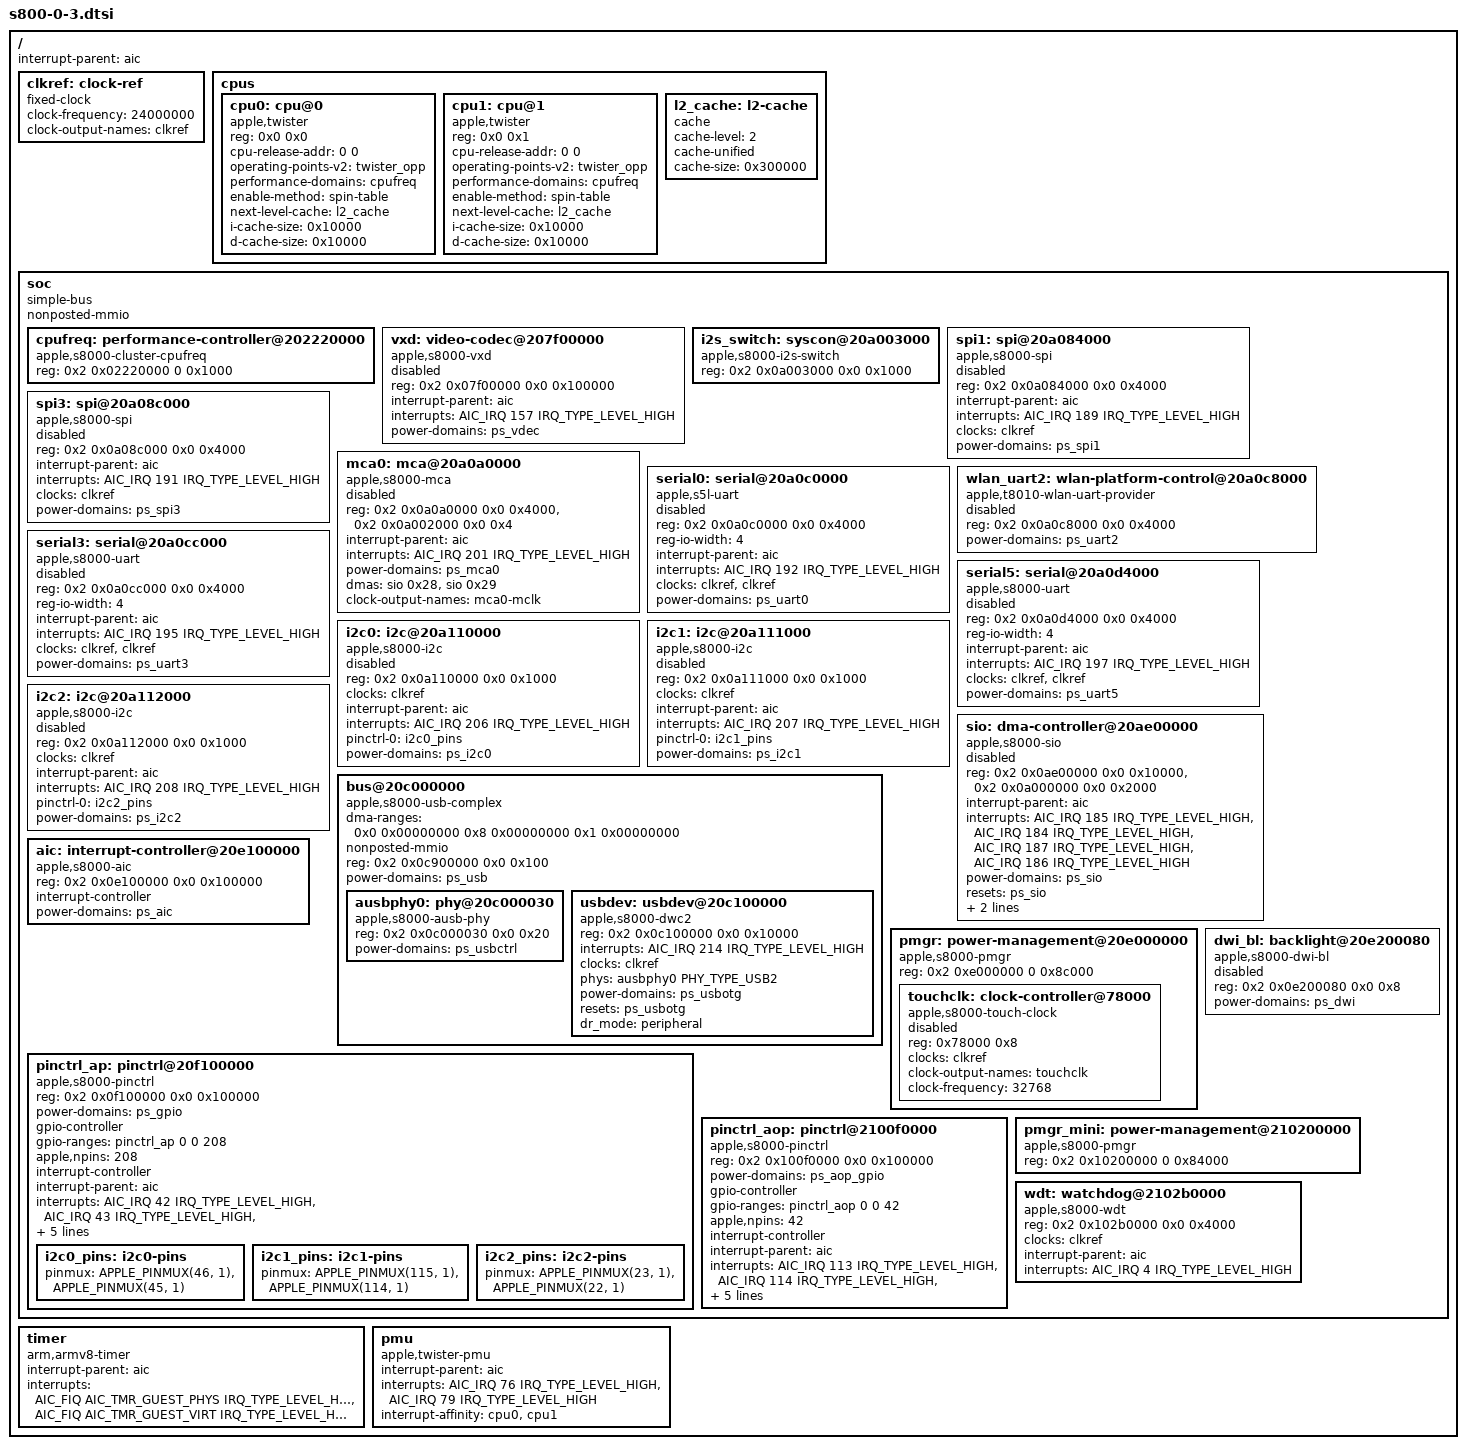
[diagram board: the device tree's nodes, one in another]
// SPDX-License-Identifier: GPL-2.0+ OR MIT
/*
 * Apple S8000/S8003 "A9" SoC
 *
 * This file contains parts common to both variants of A9
 *
 * Copyright (c) 2022, Konrad Dybcio <konradybcio@kernel.org>
 */

#include <dt-bindings/gpio/gpio.h>
#include <dt-bindings/interrupt-controller/apple-aic.h>
#include <dt-bindings/interrupt-controller/irq.h>
#include <dt-bindings/phy/phy.h>
#include <dt-bindings/pinctrl/apple.h>

/ {
	interrupt-parent = <&aic>;
	#address-cells = <2>;
	#size-cells = <2>;

	clkref: clock-ref {
		compatible = "fixed-clock";
		#clock-cells = <0>;
		clock-frequency = <24000000>;
		clock-output-names = "clkref";
	};

	cpus {
		#address-cells = <2>;
		#size-cells = <0>;

		cpu0: cpu@0 {
			compatible = "apple,twister";
			reg = <0x0 0x0>;
			cpu-release-addr = <0 0>; /* To be filled in by loader */
			operating-points-v2 = <&twister_opp>;
			performance-domains = <&cpufreq>;
			enable-method = "spin-table";
			device_type = "cpu";
			next-level-cache = <&l2_cache>;
			i-cache-size = <0x10000>;
			d-cache-size = <0x10000>;
		};

		cpu1: cpu@1 {
			compatible = "apple,twister";
			reg = <0x0 0x1>;
			cpu-release-addr = <0 0>; /* To be filled in by loader */
			operating-points-v2 = <&twister_opp>;
			performance-domains = <&cpufreq>;
			enable-method = "spin-table";
			device_type = "cpu";
			next-level-cache = <&l2_cache>;
			i-cache-size = <0x10000>;
			d-cache-size = <0x10000>;
		};

		l2_cache: l2-cache {
			compatible = "cache";
			cache-level = <2>;
			cache-unified;
			cache-size = <0x300000>;
		};
	};

	soc {
		compatible = "simple-bus";
		#address-cells = <2>;
		#size-cells = <2>;
		nonposted-mmio;
		ranges;

		cpufreq: performance-controller@202220000 {
			compatible = "apple,s8000-cluster-cpufreq", "apple,t8103-cluster-cpufreq", "apple,cluster-cpufreq";
			reg = <0x2 0x02220000 0 0x1000>;
			#performance-domain-cells = <0>;
		};

		/*
		 * Imagination MSVDX ("VXD") H.264 decoder, ADT vxd@7F00000. It
		 * has its own two-level GART, so no DART.
		 */
		vxd: video-codec@207f00000 {
			compatible = "apple,s8000-vxd";
			reg = <0x2 0x07f00000 0x0 0x100000>;
			interrupt-parent = <&aic>;
			interrupts = <AIC_IRQ 157 IRQ_TYPE_LEVEL_HIGH>;
			power-domains = <&ps_vdec>;
			status = "disabled";
		};

		i2s_switch: syscon@20a003000 {
			compatible = "apple,s8000-i2s-switch", "syscon";
			reg = <0x2 0x0a003000 0x0 0x1000>;
		};

		spi1: spi@20a084000 {
			compatible = "apple,s8000-spi", "apple,spi";
			reg = <0x2 0x0a084000 0x0 0x4000>;
			interrupt-parent = <&aic>;
			interrupts = <AIC_IRQ 189 IRQ_TYPE_LEVEL_HIGH>;
			clocks = <&clkref>;
			power-domains = <&ps_spi1>;
			#address-cells = <1>;
			#size-cells = <0>;
			status = "disabled";
		};

		spi3: spi@20a08c000 {
			compatible = "apple,s8000-spi", "apple,spi";
			reg = <0x2 0x0a08c000 0x0 0x4000>;
			interrupt-parent = <&aic>;
			interrupts = <AIC_IRQ 191 IRQ_TYPE_LEVEL_HIGH>;
			clocks = <&clkref>;
			power-domains = <&ps_spi3>;
			#address-cells = <1>;
			#size-cells = <0>;
			status = "disabled";
		};

		/* SmartIO DMA endpoints 0x28 (TX) and 0x29 (RX), from the ADT. */
		mca0: mca@20a0a0000 {
			compatible = "apple,s8000-mca";
			reg = <0x2 0x0a0a0000 0x0 0x4000>,
			      <0x2 0x0a002000 0x0 0x4>;
			reg-names = "mca", "mclk";
			interrupt-parent = <&aic>;
			interrupts = <AIC_IRQ 201 IRQ_TYPE_LEVEL_HIGH>;
			power-domains = <&ps_mca0>;
			dmas = <&sio 0x28>, <&sio 0x29>;
			dma-names = "tx", "rx";
			#clock-cells = <0>;
			clock-output-names = "mca0-mclk";
			#sound-dai-cells = <0>;
			status = "disabled";
		};

		serial0: serial@20a0c0000 {
			compatible = "apple,s5l-uart";
			reg = <0x2 0x0a0c0000 0x0 0x4000>;
			reg-io-width = <4>;
			interrupt-parent = <&aic>;
			interrupts = <AIC_IRQ 192 IRQ_TYPE_LEVEL_HIGH>;
			/* Use the bootloader-enabled clocks for now. */
			clocks = <&clkref>, <&clkref>;
			clock-names = "uart", "clk_uart_baud0";
			power-domains = <&ps_uart0>;
			status = "disabled";
		};

		/*
		 * uart2 carries the ADT's "wlan" node (wlan-pcie-uart,bcm4355):
		 * the platform-control function of the PCIe Wi-Fi module.
		 */
		wlan_uart2: wlan-platform-control@20a0c8000 {
			compatible = "apple,t8010-wlan-uart-provider";
			reg = <0x2 0x0a0c8000 0x0 0x4000>;
			power-domains = <&ps_uart2>;
			status = "disabled";
		};

		serial3: serial@20a0cc000 {
			compatible = "apple,s8000-uart", "apple,t8010-uart", "apple,s5l-uart";
			reg = <0x2 0x0a0cc000 0x0 0x4000>;
			reg-io-width = <4>;
			interrupt-parent = <&aic>;
			interrupts = <AIC_IRQ 195 IRQ_TYPE_LEVEL_HIGH>;
			/* Use the bootloader-enabled clocks for now. */
			clocks = <&clkref>, <&clkref>;
			clock-names = "uart", "clk_uart_baud0";
			power-domains = <&ps_uart3>;
			status = "disabled";
		};

		serial5: serial@20a0d4000 {
			compatible = "apple,s8000-uart", "apple,t8010-uart", "apple,s5l-uart";
			reg = <0x2 0x0a0d4000 0x0 0x4000>;
			reg-io-width = <4>;
			interrupt-parent = <&aic>;
			interrupts = <AIC_IRQ 197 IRQ_TYPE_LEVEL_HIGH>;
			/* Use the bootloader-enabled clocks for now. */
			clocks = <&clkref>, <&clkref>;
			clock-names = "uart", "clk_uart_baud0";
			power-domains = <&ps_uart5>;
			status = "disabled";
		};

		i2c0: i2c@20a110000 {
			compatible = "apple,s8000-i2c", "apple,i2c";
			reg = <0x2 0x0a110000 0x0 0x1000>;
			clocks = <&clkref>;
			interrupt-parent = <&aic>;
			interrupts = <AIC_IRQ 206 IRQ_TYPE_LEVEL_HIGH>;
			pinctrl-0 = <&i2c0_pins>;
			pinctrl-names = "default";
			power-domains = <&ps_i2c0>;
			#address-cells = <1>;
			#size-cells = <0>;
			status = "disabled";
		};

		i2c1: i2c@20a111000 {
			compatible = "apple,s8000-i2c", "apple,i2c";
			reg = <0x2 0x0a111000 0x0 0x1000>;
			clocks = <&clkref>;
			interrupt-parent = <&aic>;
			interrupts = <AIC_IRQ 207 IRQ_TYPE_LEVEL_HIGH>;
			pinctrl-0 = <&i2c1_pins>;
			pinctrl-names = "default";
			power-domains = <&ps_i2c1>;
			#address-cells = <1>;
			#size-cells = <0>;
			status = "disabled";
		};

		i2c2: i2c@20a112000 {
			compatible = "apple,s8000-i2c", "apple,i2c";
			reg = <0x2 0x0a112000 0x0 0x1000>;
			clocks = <&clkref>;
			interrupt-parent = <&aic>;
			interrupts = <AIC_IRQ 208 IRQ_TYPE_LEVEL_HIGH>;
			pinctrl-0 = <&i2c2_pins>;
			pinctrl-names = "default";
			power-domains = <&ps_i2c2>;
			#address-cells = <1>;
			#size-cells = <0>;
			status = "disabled";
		};

		/* ADT /arm-io/sio: iop,s8000, AppleA7IOP version 1 */
		sio: dma-controller@20ae00000 {
			compatible = "apple,s8000-sio";
			reg = <0x2 0x0ae00000 0x0 0x10000>,
			      <0x2 0x0a000000 0x0 0x2000>;
			reg-names = "a7iop", "shim";
			interrupt-parent = <&aic>;
			interrupts = <AIC_IRQ 185 IRQ_TYPE_LEVEL_HIGH>,
				     <AIC_IRQ 184 IRQ_TYPE_LEVEL_HIGH>,
				     <AIC_IRQ 187 IRQ_TYPE_LEVEL_HIGH>,
				     <AIC_IRQ 186 IRQ_TYPE_LEVEL_HIGH>;
			power-domains = <&ps_sio>;
			resets = <&ps_sio>;
			firmware-name = "apple/s8000-smartio.bin";
			dma-channels = <64>;
			#dma-cells = <1>;
			status = "disabled";
		};

		bus@20c000000 {
			compatible = "apple,s8000-usb-complex", "apple,s5l8960x-usb-complex", "simple-pm-bus";
			#address-cells = <2>;
			#size-cells = <2>;
			dma-ranges = <0x0 0x00000000 0x8 0x00000000 0x1 0x00000000>;
			nonposted-mmio;
			ranges;

			reg = <0x2 0x0c900000 0x0 0x100>;
			power-domains = <&ps_usb>;

			ausbphy0: phy@20c000030 {
				compatible = "apple,s8000-ausb-phy", "apple,ausb-phy";
				reg = <0x2 0x0c000030 0x0 0x20>;
				power-domains = <&ps_usbctrl>;
				#phy-cells = <1>;
				/* Tunables to be filled by loader */
			};

			usbdev: usbdev@20c100000 {
				compatible = "apple,s8000-dwc2", "apple,dwc2";
				reg = <0x2 0x0c100000 0x0 0x10000>;
				interrupts = <AIC_IRQ 214 IRQ_TYPE_LEVEL_HIGH>;
				clocks = <&clkref>;
				clock-names = "otg";
				phys = <&ausbphy0 PHY_TYPE_USB2>;
				phy-names = "usb2-phy";
				power-domains = <&ps_usbotg>;
				resets = <&ps_usbotg>;
				dr_mode = "peripheral";
			};
#if 0
			ehci0: usb-ehci@20c200000 {
				compatible = "apple,s8000-ehci", "generic-ehci";
				reg = <0x2 0x0c200000 0x0 0x10000>;
				interrupts = <AIC_IRQ 215 IRQ_TYPE_LEVEL_HIGH>;
				power-domains = <&ps_usb2host0>;
			};

			ohci0: usb-ohci@20c300000 {
				compatible = "apple,s8000-ohci", "generic-ohci";
				reg = <0x2 0x0c300000 0x0 0x10000>;
				interrupts = <AIC_IRQ 216 IRQ_TYPE_LEVEL_HIGH>;
				power-domains = <&ps_usb2host0_ohci>;
			};

			ehci1: usb-ehci@20c400000 {
				compatible = "apple,s8000-ehci", "generic-ehci";
				reg = <0x2 0x0c400000 0x0 0x10000>;
				interrupts = <AIC_IRQ 217 IRQ_TYPE_LEVEL_HIGH>;
				power-domains = <&ps_usb2host1>;
			};

			ehci2: usb-ehci@20c500000 {
				compatible = "apple,s8000-ehci", "generic-ehci";
				reg = <0x2 0x0c500000 0x0 0x10000>;
				interrupts = <AIC_IRQ 218 IRQ_TYPE_LEVEL_HIGH>;
				power-domains = <&ps_usb2host2>;
			};
#endif
		};

		pmgr: power-management@20e000000 {
			compatible = "apple,s8000-pmgr", "apple,pmgr", "syscon", "simple-mfd";
			#address-cells = <1>;
			#size-cells = <1>;

			reg = <0x2 0xe000000 0 0x8c000>;

			touchclk: clock-controller@78000 {
				compatible = "apple,s8000-touch-clock", "apple,t8010-touch-clock";
				reg = <0x78000 0x8>;
				#clock-cells = <0>;
				clocks = <&clkref>;
				clock-output-names = "touchclk";
				clock-frequency = <32768>;
				status = "disabled";
			};
		};

		aic:interrupt-controller@20e100000 {
			compatible = "apple,s8000-aic", "apple,aic";
			reg = <0x2 0x0e100000 0x0 0x100000>;
			#interrupt-cells = <3>;
			interrupt-controller;
			power-domains = <&ps_aic>;
		};

		dwi_bl: backlight@20e200080 {
			compatible = "apple,s8000-dwi-bl", "apple,dwi-bl";
			reg = <0x2 0x0e200080 0x0 0x8>;
			power-domains = <&ps_dwi>;
			status = "disabled";
		};

		pinctrl_ap: pinctrl@20f100000 {
			compatible = "apple,s8000-pinctrl", "apple,pinctrl";
			reg = <0x2 0x0f100000 0x0 0x100000>;
			power-domains = <&ps_gpio>;

			gpio-controller;
			#gpio-cells = <2>;
			gpio-ranges = <&pinctrl_ap 0 0 208>;
			apple,npins = <208>;

			interrupt-controller;
			#interrupt-cells = <2>;
			interrupt-parent = <&aic>;
			interrupts = <AIC_IRQ 42 IRQ_TYPE_LEVEL_HIGH>,
				     <AIC_IRQ 43 IRQ_TYPE_LEVEL_HIGH>,
				     <AIC_IRQ 44 IRQ_TYPE_LEVEL_HIGH>,
				     <AIC_IRQ 45 IRQ_TYPE_LEVEL_HIGH>,
				     <AIC_IRQ 46 IRQ_TYPE_LEVEL_HIGH>,
				     <AIC_IRQ 47 IRQ_TYPE_LEVEL_HIGH>,
				     <AIC_IRQ 48 IRQ_TYPE_LEVEL_HIGH>;

			i2c0_pins: i2c0-pins {
				pinmux = <APPLE_PINMUX(46, 1)>,
					 <APPLE_PINMUX(45, 1)>;
			};

			i2c1_pins: i2c1-pins {
				pinmux = <APPLE_PINMUX(115, 1)>,
					 <APPLE_PINMUX(114, 1)>;
			};

			i2c2_pins: i2c2-pins {
				pinmux = <APPLE_PINMUX(23, 1)>,
					 <APPLE_PINMUX(22, 1)>;
			};
		};

		pinctrl_aop: pinctrl@2100f0000 {
			compatible = "apple,s8000-pinctrl", "apple,pinctrl";
			reg = <0x2 0x100f0000 0x0 0x100000>;
			power-domains = <&ps_aop_gpio>;

			gpio-controller;
			#gpio-cells = <2>;
			gpio-ranges = <&pinctrl_aop 0 0 42>;
			apple,npins = <42>;

			interrupt-controller;
			#interrupt-cells = <2>;
			interrupt-parent = <&aic>;
			interrupts = <AIC_IRQ 113 IRQ_TYPE_LEVEL_HIGH>,
				     <AIC_IRQ 114 IRQ_TYPE_LEVEL_HIGH>,
				     <AIC_IRQ 115 IRQ_TYPE_LEVEL_HIGH>,
				     <AIC_IRQ 116 IRQ_TYPE_LEVEL_HIGH>,
				     <AIC_IRQ 117 IRQ_TYPE_LEVEL_HIGH>,
				     <AIC_IRQ 118 IRQ_TYPE_LEVEL_HIGH>,
				     <AIC_IRQ 119 IRQ_TYPE_LEVEL_HIGH>;
		};

		pmgr_mini: power-management@210200000 {
			compatible = "apple,s8000-pmgr", "apple,pmgr", "syscon", "simple-mfd";
			#address-cells = <1>;
			#size-cells = <1>;

			reg = <0x2 0x10200000 0 0x84000>;
		};

		wdt: watchdog@2102b0000 {
			compatible = "apple,s8000-wdt", "apple,wdt";
			reg = <0x2 0x102b0000 0x0 0x4000>;
			clocks = <&clkref>;
			interrupt-parent = <&aic>;
			interrupts = <AIC_IRQ 4 IRQ_TYPE_LEVEL_HIGH>;
		};
	};

	timer {
		compatible = "arm,armv8-timer";
		interrupt-parent = <&aic>;
		interrupt-names = "phys", "virt";
		/* Note that A9 doesn't actually have a hypervisor (EL2 is not implemented). */
		interrupts = <AIC_FIQ AIC_TMR_GUEST_PHYS IRQ_TYPE_LEVEL_HIGH>,
			     <AIC_FIQ AIC_TMR_GUEST_VIRT IRQ_TYPE_LEVEL_HIGH>;
	};

	pmu {
		compatible = "apple,twister-pmu";
		interrupt-parent = <&aic>;
		interrupts = <AIC_IRQ 76 IRQ_TYPE_LEVEL_HIGH>,
			     <AIC_IRQ 79 IRQ_TYPE_LEVEL_HIGH>;
		interrupt-affinity = <&cpu0 &cpu1>;
	};
};

#include "s800-0-3-pmgr.dtsi"

/*
 * The A9 was made by two separate fabs on two different process
 * nodes: Samsung made the S8000 (APL0898) on 14nm and TSMC made
 * the S8003 (APL1022) on 16nm. There are some minor differences
 * such as timing in cpufreq state transistions.
 */
